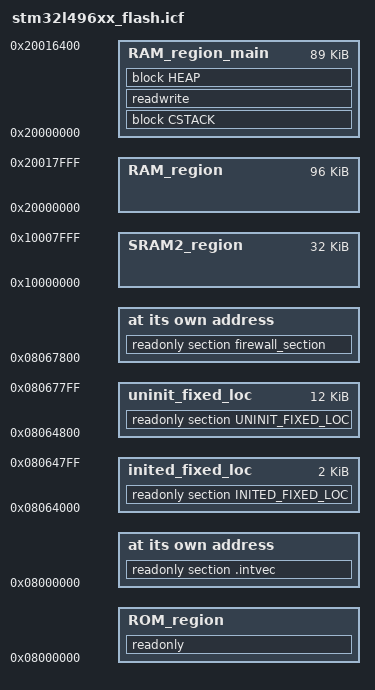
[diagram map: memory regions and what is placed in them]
/*###ICF### Section handled by ICF editor, don't touch! ****/
/*-Editor annotation file-*/
/* IcfEditorFile="$TOOLKIT_DIR$\config\ide\IcfEditor\cortex_v1_0.xml" */
/*-Specials-*/
define symbol __ICFEDIT_intvec_start__ = 0x08000000;
/*-Memory Regions-*/
define symbol __ICFEDIT_region_ROM_start__   = 0x08000000;
define symbol __ICFEDIT_region_ROM_end__     = 0x0807ffff;
define symbol __ICFEDIT_region_RAM_start__   = 0x20000000;
define symbol __ICFEDIT_region_RAM_end__     = 0x20017FFF;  /* Not all the chip RAM1 (size = 0x17FFF) is allocatable is this project. The rest will be used by the firewall runtime. */
define symbol __ICFEDIT_region_SRAM2_start__ = 0x10000000;
define symbol __ICFEDIT_region_SRAM2_end__   = 0x10007FFF;

/*-Sizes-*/
define symbol __ICFEDIT_size_cstack__ = 0x2000;
define symbol __ICFEDIT_size_heap__   = 0x11000;
/**** End of ICF editor section. ###ICF###*/

define memory mem with size = 4G;

/* Definition of the static memory section for TLS certificates, keys, and wifi configuration data at the end of the first bank:
 *  Provision of 12Kbytes.
 */
define symbol __ICFEDIT_region_FIXED_LOC_start__ = 0x08064000;
define region inited_fixed_loc = mem:[from __ICFEDIT_region_FIXED_LOC_start__ size 2K];
define region uninit_fixed_loc = mem:[from __ICFEDIT_region_FIXED_LOC_start__ + 2K size 12K];

define region ROM_region      = mem:[from __ICFEDIT_region_ROM_start__   to __ICFEDIT_region_ROM_end__] - uninit_fixed_loc;
define region RAM_region      = mem:[from __ICFEDIT_region_RAM_start__   to __ICFEDIT_region_RAM_end__];
define region SRAM2_region    = mem:[from __ICFEDIT_region_SRAM2_start__   to __ICFEDIT_region_SRAM2_end__];
define symbol __Firewall_ram_start = 0x20016400;

define region RAM_region_main      = mem:[from __ICFEDIT_region_RAM_start__   to __Firewall_ram_start ];


define block CSTACK    with alignment = 8, size = __ICFEDIT_size_cstack__   { };
define block HEAP      with alignment = 8, size = __ICFEDIT_size_heap__     { };

initialize by copy { readwrite };
do not initialize  { section .noinit };

define exported symbol __firewall_ROM_start = 0x08067800; 
place at address mem:__firewall_ROM_start { readonly section firewall_section }; 


place at address mem:__ICFEDIT_intvec_start__ { readonly section .intvec };

place in ROM_region   { readonly };
place in RAM_region_main   { block CSTACK,
                        readwrite,
                        block HEAP };
						
						
place in uninit_fixed_loc  { readonly section UNINIT_FIXED_LOC };
place in inited_fixed_loc  { readonly section INITED_FIXED_LOC };
